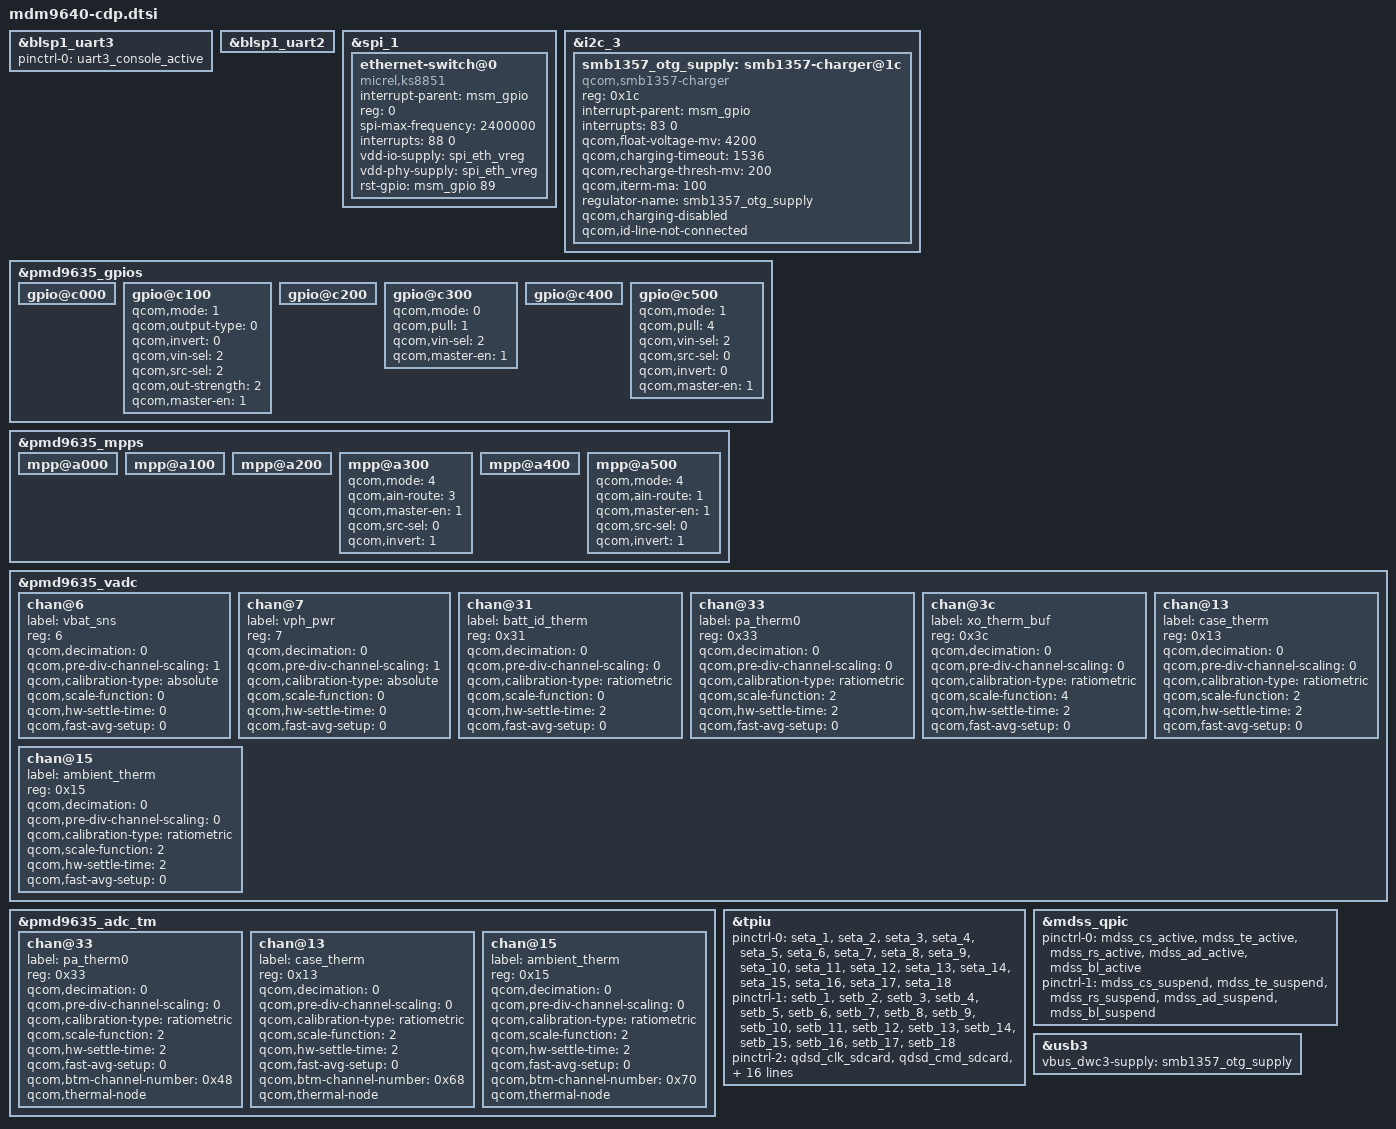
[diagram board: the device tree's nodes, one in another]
/* Copyright (c) 2014-2015, The Linux Foundation. All rights reserved.
 *
 * This program is free software; you can redistribute it and/or modify
 * it under the terms of the GNU General Public License version 2 and
 * only version 2 as published by the Free Software Foundation.
 *
 * This program is distributed in the hope that it will be useful,
 * but WITHOUT ANY WARRANTY; without even the implied warranty of
 * MERCHANTABILITY or FITNESS FOR A PARTICULAR PURPOSE.  See the
 * GNU General Public License for more details.
 */

#include "mdm9640.dtsi"
#include "mdm9640-pinctrl.dtsi"
#include "mdm9640-display.dtsi"
#include "qpic-panel-ili-hvga.dtsi"

&blsp1_uart3 {
	status = "ok";
	pinctrl-names = "default";
	pinctrl-0 = <&uart3_console_active>;
};

&blsp1_uart2 {
	status = "ok";
};

&spi_1 {
	status = "ok";
	ethernet-switch@0 {
		compatible = "micrel,ks8851";
		interrupt-parent = <&msm_gpio>;
		reg = <0>;
		spi-max-frequency = <2400000>;
		interrupts = <88 0>;
		vdd-io-supply = <&spi_eth_vreg>;
		vdd-phy-supply = <&spi_eth_vreg>;
		rst-gpio = <&msm_gpio 89 0>;
	};
};

&i2c_3 {
	smb1357_otg_supply: smb1357-charger@1c {
		compatible = "qcom,smb1357-charger";
		reg = <0x1c>;
		interrupt-parent = <&msm_gpio>;
		interrupts = <83 0>;	/* MDM GPIO 83 */
		qcom,float-voltage-mv = <4200>;
		qcom,charging-timeout = <1536>;
		qcom,recharge-thresh-mv = <200>;
		qcom,iterm-ma = <100>;
		regulator-name = "smb1357_otg_supply";
		qcom,charging-disabled;
		qcom,id-line-not-connected;
	};
};

&pmd9635_gpios {
	gpio@c000 { /* GPIO 1 */
	};

	gpio@c100 { /* GPIO 2 */
		qcom,mode = <1>;               /* Digital output */
		qcom,output-type = <0>;        /* CMOS logic */
		qcom,invert = <0>;             /* no inversion */
		qcom,vin-sel = <2>;            /* VIN 2 */
		qcom,src-sel = <2>;            /* Function 2 */
		qcom,out-strength = <2>;       /* Medium */
		qcom,master-en = <1>;          /* Enable GPIO */
		status = "ok";
	};

	gpio@c200 { /* GPIO 3 */
	};

	gpio@c300 { /* GPIO 4 */
		status = "ok";
		qcom,mode = <0>;	/* Digital input */
		qcom,pull = <1>;	/* Pull up 1.5 uA */
		qcom,vin-sel = <2>;	/* PMD9635 LDO 6 = 1.8 V */
		qcom,master-en = <1>;	/* Enable GPIO */
	};

	gpio@c400 { /* GPIO 5 */
	};

	gpio@c500 { /* GPIO 6 */
		qcom,mode = <1>;         /* Digital output*/
		qcom,pull = <4>;         /* Pulldown 10uA */
		qcom,vin-sel = <2>;      /* VIN2 */
		qcom,src-sel = <0>;      /* GPIO */
		qcom,invert = <0>;       /* Invert */
		qcom,master-en = <1>;    /* Enable GPIO */
		status = "ok";
	};
};

&pmd9635_mpps {
	mpp@a000 { /* MPP 1 */
	};

	mpp@a100 { /* MPP 2 */
	};

	mpp@a200 { /* MPP 3 */
	};

	mpp@a300 { /* MPP 4 */
		/* VADC channel 19 */
		qcom,mode = <4>;
		qcom,ain-route = <3>; /* AMUX 8 */
		qcom,master-en = <1>;
		qcom,src-sel = <0>; /* Function constant */
		qcom,invert = <1>;
		status = "ok";
	};

	mpp@a400 { /* MPP 5 */
	};

	mpp@a500 { /* MPP 6 */
		/* channel 21 */
		qcom,mode = <4>;
		qcom,ain-route = <1>; /* AMUX 6 */
		qcom,master-en = <1>;
		qcom,src-sel = <0>; /* Function constant */
		qcom,invert = <1>;
		status = "ok";
	};
};

&pmd9635_vadc {
	chan@6 {
		label = "vbat_sns";
		reg = <6>;
		qcom,decimation = <0>;
		qcom,pre-div-channel-scaling = <1>;
		qcom,calibration-type = "absolute";
		qcom,scale-function = <0>;
		qcom,hw-settle-time = <0>;
		qcom,fast-avg-setup = <0>;
	};

	chan@7 {
		label = "vph_pwr";
		reg = <7>;
		qcom,decimation = <0>;
		qcom,pre-div-channel-scaling = <1>;
		qcom,calibration-type = "absolute";
		qcom,scale-function = <0>;
		qcom,hw-settle-time = <0>;
		qcom,fast-avg-setup = <0>;
	};

	chan@31 {
		label = "batt_id_therm";
		reg = <0x31>;
		qcom,decimation = <0>;
		qcom,pre-div-channel-scaling = <0>;
		qcom,calibration-type = "ratiometric";
		qcom,scale-function = <0>;
		qcom,hw-settle-time = <2>;
		qcom,fast-avg-setup = <0>;
	};

	chan@33 {
		label = "pa_therm0";
		reg = <0x33>;
		qcom,decimation = <0>;
		qcom,pre-div-channel-scaling = <0>;
		qcom,calibration-type = "ratiometric";
		qcom,scale-function = <2>;
		qcom,hw-settle-time = <2>;
		qcom,fast-avg-setup = <0>;
	};

	chan@3c {
		label = "xo_therm_buf";
		reg = <0x3c>;
		qcom,decimation = <0>;
		qcom,pre-div-channel-scaling = <0>;
		qcom,calibration-type = "ratiometric";
		qcom,scale-function = <4>;
		qcom,hw-settle-time = <2>;
		qcom,fast-avg-setup = <0>;
	};

	chan@13 {
		label = "case_therm";
		reg = <0x13>;
		qcom,decimation = <0>;
		qcom,pre-div-channel-scaling = <0>;
		qcom,calibration-type = "ratiometric";
		qcom,scale-function = <2>;
		qcom,hw-settle-time = <2>;
		qcom,fast-avg-setup = <0>;
	};

	chan@15 {
		label = "ambient_therm";
		reg = <0x15>;
		qcom,decimation = <0>;
		qcom,pre-div-channel-scaling = <0>;
		qcom,calibration-type = "ratiometric";
		qcom,scale-function = <2>;
		qcom,hw-settle-time = <2>;
		qcom,fast-avg-setup = <0>;
	};
};

&pmd9635_adc_tm {
	chan@33 {
		label = "pa_therm0";
		reg = <0x33>;
		qcom,decimation = <0>;
		qcom,pre-div-channel-scaling = <0>;
		qcom,calibration-type = "ratiometric";
		qcom,scale-function = <2>;
		qcom,hw-settle-time = <2>;
		qcom,fast-avg-setup = <0>;
		qcom,btm-channel-number = <0x48>;
		qcom,thermal-node;
	};

	chan@13 {
		label = "case_therm";
		reg = <0x13>;
		qcom,decimation = <0>;
		qcom,pre-div-channel-scaling = <0>;
		qcom,calibration-type = "ratiometric";
		qcom,scale-function = <2>;
		qcom,hw-settle-time = <2>;
		qcom,fast-avg-setup = <0>;
		qcom,btm-channel-number = <0x68>;
		qcom,thermal-node;
	};

	chan@15 {
		label = "ambient_therm";
		reg = <0x15>;
		qcom,decimation = <0>;
		qcom,pre-div-channel-scaling = <0>;
		qcom,calibration-type = "ratiometric";
		qcom,scale-function = <2>;
		qcom,hw-settle-time = <2>;
		qcom,fast-avg-setup = <0>;
		qcom,btm-channel-number = <0x70>;
		qcom,thermal-node;
	};
};

/* CoreSight */
&tpiu {
	pinctrl-names = "seta-pctrl", "setb-pctrl", "sdcard", "trace",
			"swduart", "swdtrc", "jtag", "spmi";
	/* Mictor */
	pinctrl-0 = <&seta_1 &seta_2 &seta_3 &seta_4 &seta_5 &seta_6 &seta_7
		     &seta_8 &seta_9 &seta_10 &seta_11 &seta_12 &seta_13
		     &seta_14 &seta_15 &seta_16 &seta_17 &seta_18>;
	pinctrl-1 = <&setb_1 &setb_2 &setb_3 &setb_4 &setb_5 &setb_6 &setb_7
		     &setb_8 &setb_9 &setb_10 &setb_11 &setb_12 &setb_13
		     &setb_14 &setb_15 &setb_16 &setb_17 &setb_18>;
	/* NIDnT */
	pinctrl-2 = <&qdsd_clk_sdcard &qdsd_cmd_sdcard
		    &qdsd_data0_sdcard &qdsd_data1_sdcard
		    &qdsd_data2_sdcard &qdsd_data3_sdcard>;
	pinctrl-3 = <&qdsd_clk_trace &qdsd_cmd_trace
		    &qdsd_data0_trace &qdsd_data1_trace
		    &qdsd_data2_trace &qdsd_data3_trace>;
	pinctrl-4 = <&qdsd_cmd_swduart &qdsd_data0_swduart
		    &qdsd_data1_swduart &qdsd_data2_swduart
		    &qdsd_data3_swduart>;
	pinctrl-5 = <&qdsd_clk_swdtrc &qdsd_cmd_swdtrc
		    &qdsd_data0_swdtrc &qdsd_data1_swdtrc
		    &qdsd_data2_swdtrc &qdsd_data3_swdtrc>;
	pinctrl-6 = <&qdsd_cmd_jtag &qdsd_data0_jtag
		    &qdsd_data1_jtag &qdsd_data2_jtag
		    &qdsd_data3_jtag>;
	pinctrl-7 = <&qdsd_clk_spmi &qdsd_cmd_spmi
		    &qdsd_data0_spmi &qdsd_data3_spmi>;
};

/* Display */
&mdss_qpic {
        pinctrl-names= "mdss_default", "mdss_sleep";
        pinctrl-0 = <&mdss_cs_active &mdss_te_active &mdss_rs_active
                        &mdss_ad_active &mdss_bl_active>;
        pinctrl-1 = <&mdss_cs_suspend &mdss_te_suspend
                &mdss_rs_suspend &mdss_ad_suspend &mdss_bl_suspend>;
};

&usb3 {
	vbus_dwc3-supply = <&smb1357_otg_supply>;
};
